# RK3399-AP register map
File version: 1
CPU: CA7 r0p1, little endian, MPU, FPU, I-cache, D-cache, VTOR, 4 interrupt priority bits, 0 interrupts
Registers are 32-bit, read-write, reset 0x0 unless marked. A register's access mark holds for its fields unless they carry their own. Offsets are from the block's base; [hi:lo] are bit positions.

## GPIO0
Base 0xFF720000
Same registers: GPIO1 0xFF730000, GPIO2 0xFF780000, GPIO3 0xFF788000, GPIO4 0xFF790000
0x00 GPIO_SWPORTA_DR — Port A data register
  [31:0] GPIO_SWPORTA_DR — Values written to this register are output on the I/O signals for Port A if the corresponding data direction bits for Port A are set to Output mode. The value read back is equal to the last value written to this register.
0x04 GPIO_SWPORTA_DDR — Port A data direction register
  [31:0] GPIO_SWPORTA_DDR — Values written to this register independently control the direction of the corresponding data bit in Port A. 0: Input (default) 1: Output
0x30 GPIO_INTEN — Interrupt enable register
  [31:0] GPIO_INT_EN — Allows each bit of Port A to be configured for interrupts. Whenever a 1 is written to a bit of this register, it configures the corresponding bit on Port A to become an interrupt; otherwise, Port A operates as a normal GPIO signal. Interrupts are disabled on the corresponding bits of Port A if the corresponding data direction register is set to Output. 0: Configure Port A bit as normal GPIO signal (default) 1: Configure Port A bit as interrupt
0x34 GPIO_INTMASK — Interrupt mask register
  [31:0] GPIO_INT_MASK — Controls whether an interrupt on Port A can create an interrupt for the interrupt controller by not masking it. Whenever a 1 is written to a bit in this register, it masks the interrupt generation capability for this signal; otherwise interrupts are allowed through. 0: Interrupt bits are unmasked (default) 1: Mask interrupt
0x38 GPIO_INTTYPE_LEVEL — Interrupt level register
  [31:0] GPIO_INTTYPE_LEVEL — Controls the type of interrupt that can occur on Port A. 0: Level-sensitive (default) 1: Edge-sensitive
0x3C GPIO_INT_POLARITY — Interrupt polarity register
  [31:0] GPIO_INT_POLARITY — Controls the polarity of edge or level sensitivity that can occur on input of Port A. 0: Active-low (default) 1: Active-high
0x40 GPIO_INT_STATUS ro — Interrupt status of port A
  [31:0] GPIO_INT_STATUS — Interrupt status of Port A
0x44 GPIO_INT_RAWSTATUS ro — Raw Interrupt status of port A
  [31:0] GPIO_INT_RAWSTATUS — Raw interrupt of status of Port A (premasking bits)
0x48 GPIO_DEBOUNCE — Debounce enable register
  [31:0] GPIO_DEBOUNCE — Controls whether an external signal that is the source of an interrupt needs to be debounced to remove any spurious glitches. Writing a 1 to a bit in this register enables the debouncing circuitry. A signal must be valid for two periods of an external clock before it is internally processed. 0: No debounce (default) 1: Enable debounce
0x4C GPIO_PORTA_EOI wo — Port A clear interrupt register
  [31:0] GPIO_PORTA_EOI — Controls the clearing of edge type interrupts from Port A. When a 1 is written into a corresponding bit of this register, the interrupt is cleared. All interrupts are cleared when Port A is not configured for interrupts. 0: No interrupt clear (default) 1: Clear interrupt
0x50 GPIO_EXT_PORTA ro — Port A external port register
  [31:0] GPIO_EXT_PORTA — When Port A is configured as Input, then reading this location reads the values on the signal. When the data direction of Port A is set as Output, reading this location reads the data register for Port A.
0x60 GPIO_LS_SYNC — Level_sensitive synchronization enable register
  [0] GPIO_LS_SYNC — Writing a 1 to this register results in all level-sensitive interrupts being synchronized to pclk_intr. 0: No synchronization to pclk_intr (default) 1: Synchronize to pclk_intr

## ISP0_MMU0
Base 0xFF914000
Same registers: IEP_MMU 0xFF670800, VOPL_MMU 0xFF8F0300, VOPB_MMU 0xFF900300, ISP0_MMU1 0xFF915000, ISP1_MMU0 0xFF924000, ISP1_MMU1 0xFF925000, HDCP_MMU 0xFF930000
0x00 MMU_DTE_ADDR — MMU current page table address
  [31:0] MMU_DTE_ADDR — page table address
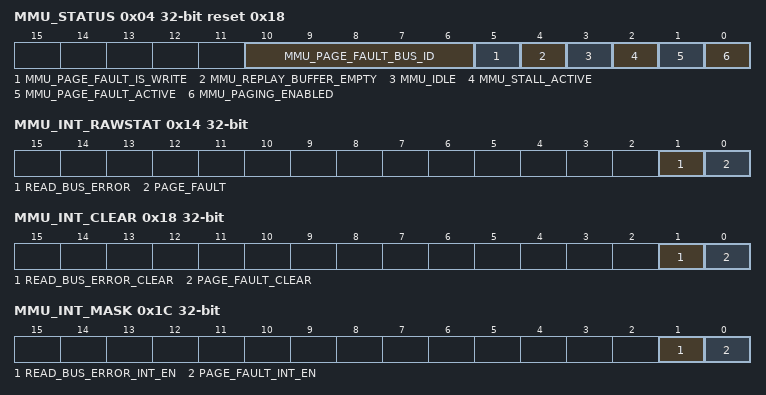
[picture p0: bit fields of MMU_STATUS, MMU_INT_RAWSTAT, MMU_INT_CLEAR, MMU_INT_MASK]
0x04 MMU_STATUS ro reset 0x18
  [10:6] MMU_PAGE_FAULT_BUS_ID — Index of master responsible for the last page fault
  [5] MMU_PAGE_FAULT_IS_WRITE — The direction of access for last page fault: 0: read 1:write
  [4] MMU_REPLAY_BUFFER_EMPTY — 1：The MMU replay buffer is empty.
  [3] MMU_IDLE — the MMu is idle when accesses are being translated and there are no unfinished translated access. The MMU_IDLE signal only reports idle when the MMU processor is idle and accesses are active on the external bus. Note: the MMU can be idle in page fault mode. 1: MMU is idle
  [2] MMU_STALL_ACTIVE — MMU stall mode currently enabled. The mode is enabled by command. 1: MMU is in stall active status
  [1] MMU_PAGE_FAULT_ACTIVE — MMU page fault mode currently enabled.The mode is enabled by command 1: page fault is active
  [0] MMU_PAGING_ENABLED — 0: paging is disabled 1: Paging is enabled
0x08 MMU_CMD — MMU command register
  [2:0] MMU_CMD — 0: MMU_ENABLE_PAGING. enable paging. 1: MMU_DISABLE_PAGING. disable paging. 2: MMU_ENABLE_STALL. turn on stall mode. 3: MMU_DISABLE_STALL. turn off stall mode. 4: MMU_ZAP_CACHE. zap the entire page table cache. 5: MMU_PAGE_FAULT_DONE. leave page fault mode. 6: MMU_FORCE_RESET. reset the mmu. The MMU_ENABLE_STALL command can always be issued. Other commands are ignored unless the MMU is idle or stalled.
0x0C MMU_PAGE_FAULT_ADDR ro — MMU logic address of last page fault register
  [31:0] MMU_PAGE_FAULT_ADDR — address of last page fault
0x10 MMU_ZAP_ONE_LINE — MMU zap cache line register
  [31:0] MMU_ZAP_ONE_LINE — address to be invalidated from the page table cache.
0x14 MMU_INT_RAWSTAT ro — MMU raw interrupt status register
  [1] READ_BUS_ERROR, [0] PAGE_FAULT
0x18 MMU_INT_CLEAR — MMU interrupt clear register
  [1] READ_BUS_ERROR_CLEAR — read bus error interrupt clear. write 1 to this register can clear read bus error interrupt.
  [0] PAGE_FAULT_CLEAR — page fault interrupt clear, write 1 to this register can clear page fault interrupt.
0x1C MMU_INT_MASK — MMU interrupt mask register
  [1] READ_BUS_ERROR_INT_EN — read bus error interrupt enable
  [0] PAGE_FAULT_INT_EN — page fault interrupt enable
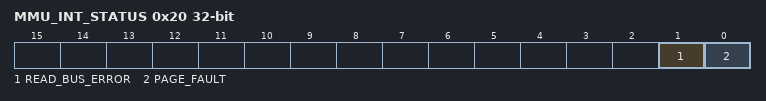
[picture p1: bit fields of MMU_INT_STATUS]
0x20 MMU_INT_STATUS access per field — MMU interrupt status register
  [1] READ_BUS_ERROR rw — read bus error interrupt
  [0] PAGE_FAULT ro — page fault interrupt
0x24 MMU_AUTO_GATING — clock atuo gating register
  [0] MMU_ATUO_GATING — mmu clock auto gating when it is 1, the mmu will auto gating itself
